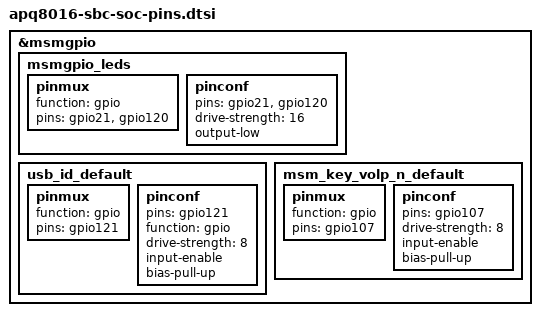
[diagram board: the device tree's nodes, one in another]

#include <dt-bindings/gpio/gpio.h>

&msmgpio {

	msmgpio_leds: msmgpio_leds {
		pinmux {
			function = "gpio";
			pins = "gpio21", "gpio120";
		};
		pinconf {
			pins = "gpio21", "gpio120";
			drive-strength = <16>;
			output-low;
		};
	};

	usb_id_default: usb_id_default {
		pinmux {
			function = "gpio";
			pins = "gpio121";
		};

		pinconf {
			pins = "gpio121";
			function = "gpio";
			drive-strength = <8>;
			input-enable;
			bias-pull-up;
		};
	};
	msm_key_volp_n_default: msm_key_volp_n_default {
		pinmux {
			function = "gpio";
			pins = "gpio107";
		};
		pinconf {
			pins = "gpio107";
			drive-strength = <8>;
			input-enable;
			bias-pull-up;
		};
	};
};
